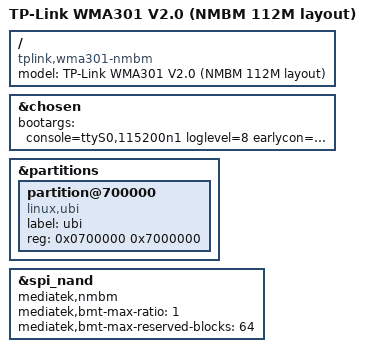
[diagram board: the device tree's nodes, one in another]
// SPDX-License-Identifier: GPL-2.0-or-later OR MIT

/dts-v1/;
#include "mt7981b-tplink-wma301-common.dtsi"

/ {
	model = "TP-Link WMA301 V2.0 (NMBM 112M layout)";
	compatible = "tplink,wma301-nmbm", "mediatek,mt7981";
};

&chosen {
	bootargs = "console=ttyS0,115200n1 loglevel=8 earlycon=uart8250,mmio32,0x11002000";
};

&partitions {
	partition@700000 {
		compatible = "linux,ubi";
		label = "ubi";
		reg = <0x0700000 0x7000000>;
	};
};

&spi_nand {
	mediatek,nmbm;
	mediatek,bmt-max-ratio = <1>;
	mediatek,bmt-max-reserved-blocks = <64>;
};
